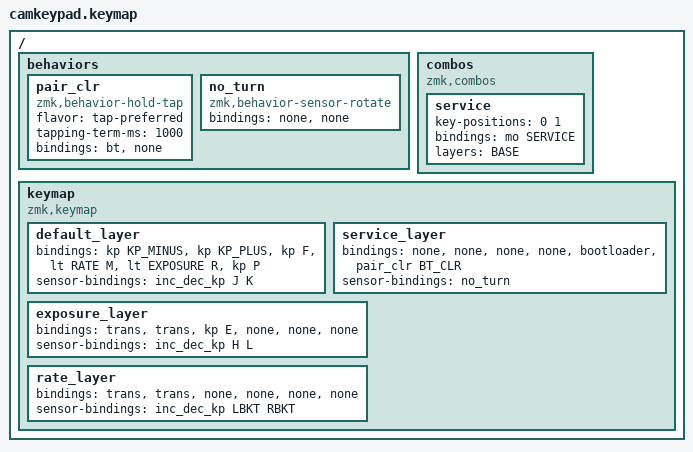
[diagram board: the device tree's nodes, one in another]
#include <behaviors.dtsi>
#include <dt-bindings/zmk/bt.h>
#include <dt-bindings/zmk/keys.h>

// src/status_screen.c shows SERVICE while this layer is active, so keep the numbers in step.
#define BASE 0
#define SERVICE 1
#define EXPOSURE 2
#define RATE 3

/ {
    behaviors {
        // Losing the pairing costs more than a reset, so clearing it takes a one-second hold.
        // Tap-preferred, so pressing another key during the hold doesn't clear it early.
        pair_clr: pair_clr {
            compatible = "zmk,behavior-hold-tap";
            #binding-cells = <2>;
            flavor = "tap-preferred";
            tapping-term-ms = <1000>;
            bindings = <&bt>, <&none>;
        };

        no_turn: no_turn {
            compatible = "zmk,behavior-sensor-rotate";
            #sensor-binding-cells = <0>;
            bindings = <&none>, <&none>;
        };
    };

    // A combo, because making the zoom keys hold-taps would break their key repeat.
    combos {
        compatible = "zmk,combos";

        service {
            key-positions = <0 1>;
            bindings = <&mo SERVICE>;
            layers = <BASE>;
        };
    };

    keymap {
        compatible = "zmk,keymap";

        default_layer {
            // Plain letters, so any Bluetooth keyboard works as a remote too. R = shutter or
            // start/stop video, P = pause/resume, M = photo/video, F = auto/manual focus.
            // Holding the zoom keys zooms smoothly through Android key repeat. Holding start/stop
            // selects the exposure layer and holding mode the rate layer, so R and M are sent on
            // release.
            bindings = <&kp KP_MINUS &kp KP_PLUS &kp F &lt RATE M &lt EXPOSURE R &kp P>;
            // Manual focus, J farther and K nearer. ZMK reads a right turn as its second
            // direction with this wiring.
            sensor-bindings = <&inc_dec_kp J K>;
        };

        // Hold both zoom keys. Start/stop enters the bootloader; hold pause to clear the pairing.
        service_layer {
            bindings = <&none &none &none &none &bootloader &pair_clr BT_CLR>;
            sensor-bindings = <&no_turn>;
        };

        // Hold start/stop. The encoder sets exposure, H down and L up; its click, E, locks it.
        exposure_layer {
            bindings = <&trans &trans &kp E &none &none &none>;
            sensor-bindings = <&inc_dec_kp H L>;
        };

        // Hold mode. The encoder sets the time-lapse rate, [ slower and ] faster.
        rate_layer {
            bindings = <&trans &trans &none &none &none &none>;
            sensor-bindings = <&inc_dec_kp LBKT RBKT>;
        };
    };
};
